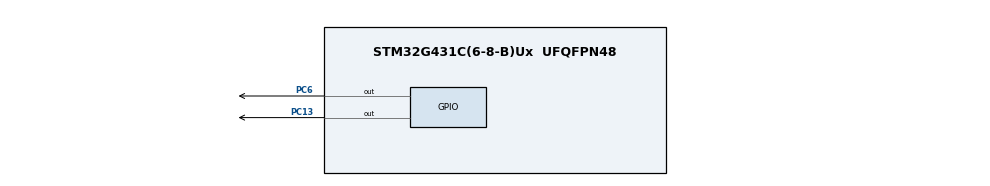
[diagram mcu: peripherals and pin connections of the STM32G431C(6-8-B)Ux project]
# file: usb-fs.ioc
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Mcu.Family=STM32G4
Mcu.Name=STM32G431C(6-8-B)Ux
Mcu.Package=UFQFPN48
NVIC.PriorityGroup=NVIC_PRIORITYGROUP_4
PA13.Mode=Serial_Wire
PA13.Signal=SYS_JTMS-SWDIO
PA14.Mode=Serial_Wire
PA14.Signal=SYS_JTCK-SWCLK
PC13.Signal=GPIO_Output
PC6.Signal=GPIO_Output
PF0-OSC_IN.Mode=HSE-External-Oscillator
PF0-OSC_IN.Signal=RCC_OSC_IN
PF1-OSC_OUT.Mode=HSE-External-Oscillator
PF1-OSC_OUT.Signal=RCC_OSC_OUT
ProjectManager.HeapSize=0x200
ProjectManager.StackSize=0x400
ProjectManager.TargetToolchain=STM32CubeIDE
RCC.ADC12Freq_Value=100000000
RCC.AHBFreq_Value=100000000
RCC.APB1Freq_Value=100000000
RCC.APB1TimFreq_Value=100000000
RCC.APB2Freq_Value=100000000
RCC.APB2TimFreq_Value=100000000
RCC.CK48CLockSelection=RCC_USBCLKSOURCE_HSI48
RCC.CortexFreq_Value=100000000
RCC.EXTERNAL_CLOCK_VALUE=12288000
RCC.HCLKFreq_Value=100000000
RCC.HSI48_VALUE=48000000
RCC.HSI_VALUE=16000000
RCC.LSE_VALUE=32768
RCC.PLLM=RCC_PLLM_DIV2
RCC.PLLN=25
RCC.SYSCLKFreq_VALUE=100000000
RCC.SYSCLKSource=RCC_SYSCLKSOURCE_PLLCLK
RCC.USBFreq_Value=48000000
RCC.VCOOutputFreq_Value=200000000
VP_SYS_VS_DBSignals.Mode=DisableDeadBatterySignals
board=custom

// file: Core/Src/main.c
/* USER CODE BEGIN Header */
/**
  ******************************************************************************
  * @file           : main.c
  * @brief          : Main program body
  ******************************************************************************
  * @attention
  *
  * Copyright (c) 2025 STMicroelectronics.
  * All rights reserved.
  *
  * This software is licensed under terms that can be found in the LICENSE file
  * in the root directory of this software component.
  * If no LICENSE file comes with this software, it is provided AS-IS.
  *
  ******************************************************************************
  */
/* USER CODE END Header */
#include "main.h"

/* USER CODE BEGIN Includes */
//#include "usbd_cdc_if.h"
//#include "Serial/sys_serial.h"
/* USER CODE END Includes */

/* USER CODE BEGIN PTD */
//typedef struct __attribute__((packed))
//{
//  uint8_t sop;
//  uint8_t cmd : 3;
//  uint8_t length : 5;
//  uint8_t data[32];
//  uint16_t crc;
//  uint8_t eop;
//} SYS_SERIAL_PacketTypeDef;

/* USER CODE END PTD */

/* USER CODE BEGIN PV */
//SYS_SERIAL_PacketTypeDef packetBuf = {0xAA,
//                                      0,
//                                      0,
//                                      {0},
//                                      0xF0F0,
//                                      0x55};
/* USER CODE END PV */

void SystemClock_Config(void);
static void MX_GPIO_Init(void);

/* USER CODE BEGIN 0 */
//int _write(int file, char *ptr, int len) {
//    CDC_Transmit_FS((uint8_t*) ptr, len); return len;
//}
/* USER CODE END 0 */

int main(void)
{

  /* MCU Configuration--------------------------------------------------------*/

  /* Reset of all peripherals, Initializes the Flash interface and the Systick. */
  LL_APB2_GRP1_EnableClock(LL_APB2_GRP1_PERIPH_SYSCFG);
  LL_APB1_GRP1_EnableClock(LL_APB1_GRP1_PERIPH_PWR);

  /* System interrupt init*/
  NVIC_SetPriorityGrouping(NVIC_PRIORITYGROUP_4);

  /* SysTick_IRQn interrupt configuration */
  NVIC_SetPriority(SysTick_IRQn, NVIC_EncodePriority(NVIC_GetPriorityGrouping(),15, 0));

  /** Disable the internal Pull-Up in Dead Battery pins of UCPD peripheral
  */
  LL_PWR_DisableUCPDDeadBattery();

  /* Configure the system clock */
  SystemClock_Config();

  /* Initialize all configured peripherals */
  MX_GPIO_Init();
  /* USER CODE BEGIN 2 */
//  uint32_t *pTemp = (uint32_t *)&testVar;
//  packetBuf.data[0] = (uint8_t)(*pTemp >> 24);
//  packetBuf.data[1] = (uint8_t)(*pTemp >> 16);
//  packetBuf.data[2] = (uint8_t)(*pTemp >> 8);
//  packetBuf.data[3] = (uint8_t)(*pTemp >> 0);
//  packetBuf.length = 4;

  /* USER CODE END 2 */

  /* Infinite loop */
  while (1)
  {

    /* USER CODE BEGIN 3 */
//	  CDC_Transmit_FS((uint8_t *)&packetBuf, sizeof(packetBuf));
//    printf("%d\r\n", sizeof(packetBuf));
//    SYS_Serial_SendSamples(&vcp, testVar1, 8);
//    HAL_Delay(2000);
    LL_GPIO_TogglePin(GPIOC, LL_GPIO_PIN_6);
    LL_GPIO_TogglePin(GPIOC, LL_GPIO_PIN_13);
    LL_mDelay(1000);
  }
  /* USER CODE END 3 */
}

void SystemClock_Config(void)
{
  LL_FLASH_SetLatency(LL_FLASH_LATENCY_3);
  while(LL_FLASH_GetLatency() != LL_FLASH_LATENCY_3)
  {
  }
  LL_PWR_SetRegulVoltageScaling(LL_PWR_REGU_VOLTAGE_SCALE1);
  LL_RCC_HSI_Enable();
   /* Wait till HSI is ready */
  while(LL_RCC_HSI_IsReady() != 1)
  {
  }

  LL_RCC_HSI_SetCalibTrimming(64);
  LL_RCC_PLL_ConfigDomain_SYS(LL_RCC_PLLSOURCE_HSI, LL_RCC_PLLM_DIV_2, 25, LL_RCC_PLLR_DIV_2);
  LL_RCC_PLL_EnableDomain_SYS();
  LL_RCC_PLL_Enable();
   /* Wait till PLL is ready */
  while(LL_RCC_PLL_IsReady() != 1)
  {
  }

  LL_RCC_SetSysClkSource(LL_RCC_SYS_CLKSOURCE_PLL);
  LL_RCC_SetAHBPrescaler(LL_RCC_SYSCLK_DIV_2);
   /* Wait till System clock is ready */
  while(LL_RCC_GetSysClkSource() != LL_RCC_SYS_CLKSOURCE_STATUS_PLL)
  {
  }

  /* Insure 1us transition state at intermediate medium speed clock*/
  for (__IO uint32_t i = (170 >> 1); i !=0; i--);

  /* Set AHB prescaler*/
  LL_RCC_SetAHBPrescaler(LL_RCC_SYSCLK_DIV_1);
  LL_RCC_SetAPB1Prescaler(LL_RCC_APB1_DIV_1);
  LL_RCC_SetAPB2Prescaler(LL_RCC_APB2_DIV_1);

  LL_Init1msTick(100000000);

  LL_SetSystemCoreClock(100000000);
}

static void MX_GPIO_Init(void)
{
  LL_GPIO_InitTypeDef GPIO_InitStruct = {0};

  /* GPIO Ports Clock Enable */
  LL_AHB2_GRP1_EnableClock(LL_AHB2_GRP1_PERIPH_GPIOC);
  LL_AHB2_GRP1_EnableClock(LL_AHB2_GRP1_PERIPH_GPIOF);
  LL_AHB2_GRP1_EnableClock(LL_AHB2_GRP1_PERIPH_GPIOG);
  LL_AHB2_GRP1_EnableClock(LL_AHB2_GRP1_PERIPH_GPIOA);
  LL_AHB2_GRP1_EnableClock(LL_AHB2_GRP1_PERIPH_GPIOB);

  /**/
  LL_GPIO_ResetOutputPin(GPIOC, LL_GPIO_PIN_13);

  /**/
  LL_GPIO_ResetOutputPin(GPIOC, LL_GPIO_PIN_6);

  /**/
  GPIO_InitStruct.Pin = LL_GPIO_PIN_13;
  GPIO_InitStruct.Mode = LL_GPIO_MODE_OUTPUT;
  GPIO_InitStruct.Speed = LL_GPIO_SPEED_FREQ_LOW;
  GPIO_InitStruct.OutputType = LL_GPIO_OUTPUT_PUSHPULL;
  GPIO_InitStruct.Pull = LL_GPIO_PULL_NO;
  LL_GPIO_Init(GPIOC, &GPIO_InitStruct);

  /**/
  GPIO_InitStruct.Pin = LL_GPIO_PIN_14;
  GPIO_InitStruct.Mode = LL_GPIO_MODE_ANALOG;
  GPIO_InitStruct.Pull = LL_GPIO_PULL_NO;
  LL_GPIO_Init(GPIOC, &GPIO_InitStruct);

  /**/
  GPIO_InitStruct.Pin = LL_GPIO_PIN_15;
  GPIO_InitStruct.Mode = LL_GPIO_MODE_ANALOG;
  GPIO_InitStruct.Pull = LL_GPIO_PULL_NO;
  LL_GPIO_Init(GPIOC, &GPIO_InitStruct);

  /**/
  GPIO_InitStruct.Pin = LL_GPIO_PIN_10;
  GPIO_InitStruct.Mode = LL_GPIO_MODE_ANALOG;
  GPIO_InitStruct.Pull = LL_GPIO_PULL_NO;
  LL_GPIO_Init(GPIOG, &GPIO_InitStruct);

  /**/
  GPIO_InitStruct.Pin = LL_GPIO_PIN_0;
  GPIO_InitStruct.Mode = LL_GPIO_MODE_ANALOG;
  GPIO_InitStruct.Pull = LL_GPIO_PULL_NO;
  LL_GPIO_Init(GPIOA, &GPIO_InitStruct);

  /**/
  GPIO_InitStruct.Pin = LL_GPIO_PIN_1;
  GPIO_InitStruct.Mode = LL_GPIO_MODE_ANALOG;
  GPIO_InitStruct.Pull = LL_GPIO_PULL_NO;
  LL_GPIO_Init(GPIOA, &GPIO_InitStruct);

  /**/
  GPIO_InitStruct.Pin = LL_GPIO_PIN_2;
  GPIO_InitStruct.Mode = LL_GPIO_MODE_ANALOG;
  GPIO_InitStruct.Pull = LL_GPIO_PULL_NO;
  LL_GPIO_Init(GPIOA, &GPIO_InitStruct);

  /**/
  GPIO_InitStruct.Pin = LL_GPIO_PIN_3;
  GPIO_InitStruct.Mode = LL_GPIO_MODE_ANALOG;
  GPIO_InitStruct.Pull = LL_GPIO_PULL_NO;
  LL_GPIO_Init(GPIOA, &GPIO_InitStruct);

  /**/
  GPIO_InitStruct.Pin = LL_GPIO_PIN_4;
  GPIO_InitStruct.Mode = LL_GPIO_MODE_ANALOG;
  GPIO_InitStruct.Pull = LL_GPIO_PULL_NO;
  LL_GPIO_Init(GPIOA, &GPIO_InitStruct);

  /**/
  GPIO_InitStruct.Pin = LL_GPIO_PIN_5;
  GPIO_InitStruct.Mode = LL_GPIO_MODE_ANALOG;
  GPIO_InitStruct.Pull = LL_GPIO_PULL_NO;
  LL_GPIO_Init(GPIOA, &GPIO_InitStruct);

  /**/
  GPIO_InitStruct.Pin = LL_GPIO_PIN_6;
  GPIO_InitStruct.Mode = LL_GPIO_MODE_ANALOG;
  GPIO_InitStruct.Pull = LL_GPIO_PULL_NO;
  LL_GPIO_Init(GPIOA, &GPIO_InitStruct);

  /**/
  GPIO_InitStruct.Pin = LL_GPIO_PIN_7;
  GPIO_InitStruct.Mode = LL_GPIO_MODE_ANALOG;
  GPIO_InitStruct.Pull = LL_GPIO_PULL_NO;
  LL_GPIO_Init(GPIOA, &GPIO_InitStruct);

  /**/
  GPIO_InitStruct.Pin = LL_GPIO_PIN_4;
  GPIO_InitStruct.Mode = LL_GPIO_MODE_ANALOG;
  GPIO_InitStruct.Pull = LL_GPIO_PULL_NO;
  LL_GPIO_Init(GPIOC, &GPIO_InitStruct);

  /**/
  GPIO_InitStruct.Pin = LL_GPIO_PIN_0;
  GPIO_InitStruct.Mode = LL_GPIO_MODE_ANALOG;
  GPIO_InitStruct.Pull = LL_GPIO_PULL_NO;
  LL_GPIO_Init(GPIOB, &GPIO_InitStruct);

  /**/
  GPIO_InitStruct.Pin = LL_GPIO_PIN_1;
  GPIO_InitStruct.Mode = LL_GPIO_MODE_ANALOG;
  GPIO_InitStruct.Pull = LL_GPIO_PULL_NO;
  LL_GPIO_Init(GPIOB, &GPIO_InitStruct);

  /**/
  GPIO_InitStruct.Pin = LL_GPIO_PIN_2;
  GPIO_InitStruct.Mode = LL_GPIO_MODE_ANALOG;
  GPIO_InitStruct.Pull = LL_GPIO_PULL_NO;
  LL_GPIO_Init(GPIOB, &GPIO_InitStruct);

  /**/
  GPIO_InitStruct.Pin = LL_GPIO_PIN_10;
  GPIO_InitStruct.Mode = LL_GPIO_MODE_ANALOG;
  GPIO_InitStruct.Pull = LL_GPIO_PULL_NO;
  LL_GPIO_Init(GPIOB, &GPIO_InitStruct);

  /**/
  GPIO_InitStruct.Pin = LL_GPIO_PIN_11;
  GPIO_InitStruct.Mode = LL_GPIO_MODE_ANALOG;
  GPIO_InitStruct.Pull = LL_GPIO_PULL_NO;
  LL_GPIO_Init(GPIOB, &GPIO_InitStruct);

  /**/
  GPIO_InitStruct.Pin = LL_GPIO_PIN_12;
  GPIO_InitStruct.Mode = LL_GPIO_MODE_ANALOG;
  GPIO_InitStruct.Pull = LL_GPIO_PULL_NO;
  LL_GPIO_Init(GPIOB, &GPIO_InitStruct);

  /**/
  GPIO_InitStruct.Pin = LL_GPIO_PIN_13;
  GPIO_InitStruct.Mode = LL_GPIO_MODE_ANALOG;
  GPIO_InitStruct.Pull = LL_GPIO_PULL_NO;
  LL_GPIO_Init(GPIOB, &GPIO_InitStruct);

  /**/
  GPIO_InitStruct.Pin = LL_GPIO_PIN_14;
  GPIO_InitStruct.Mode = LL_GPIO_MODE_ANALOG;
  GPIO_InitStruct.Pull = LL_GPIO_PULL_NO;
  LL_GPIO_Init(GPIOB, &GPIO_InitStruct);

  /**/
  GPIO_InitStruct.Pin = LL_GPIO_PIN_15;
  GPIO_InitStruct.Mode = LL_GPIO_MODE_ANALOG;
  GPIO_InitStruct.Pull = LL_GPIO_PULL_NO;
  LL_GPIO_Init(GPIOB, &GPIO_InitStruct);

  /**/
  GPIO_InitStruct.Pin = LL_GPIO_PIN_6;
  GPIO_InitStruct.Mode = LL_GPIO_MODE_OUTPUT;
  GPIO_InitStruct.Speed = LL_GPIO_SPEED_FREQ_LOW;
  GPIO_InitStruct.OutputType = LL_GPIO_OUTPUT_PUSHPULL;
  GPIO_InitStruct.Pull = LL_GPIO_PULL_NO;
  LL_GPIO_Init(GPIOC, &GPIO_InitStruct);

  /**/
  GPIO_InitStruct.Pin = LL_GPIO_PIN_8;
  GPIO_InitStruct.Mode = LL_GPIO_MODE_ANALOG;
  GPIO_InitStruct.Pull = LL_GPIO_PULL_NO;
  LL_GPIO_Init(GPIOA, &GPIO_InitStruct);

  /**/
  GPIO_InitStruct.Pin = LL_GPIO_PIN_9;
  GPIO_InitStruct.Mode = LL_GPIO_MODE_ANALOG;
  GPIO_InitStruct.Pull = LL_GPIO_PULL_NO;
  LL_GPIO_Init(GPIOA, &GPIO_InitStruct);

  /**/
  GPIO_InitStruct.Pin = LL_GPIO_PIN_10;
  GPIO_InitStruct.Mode = LL_GPIO_MODE_ANALOG;
  GPIO_InitStruct.Pull = LL_GPIO_PULL_NO;
  LL_GPIO_Init(GPIOA, &GPIO_InitStruct);

  /**/
  GPIO_InitStruct.Pin = LL_GPIO_PIN_11;
  GPIO_InitStruct.Mode = LL_GPIO_MODE_ANALOG;
  GPIO_InitStruct.Pull = LL_GPIO_PULL_NO;
  LL_GPIO_Init(GPIOA, &GPIO_InitStruct);

  /**/
  GPIO_InitStruct.Pin = LL_GPIO_PIN_12;
  GPIO_InitStruct.Mode = LL_GPIO_MODE_ANALOG;
  GPIO_InitStruct.Pull = LL_GPIO_PULL_NO;
  LL_GPIO_Init(GPIOA, &GPIO_InitStruct);

  /**/
  GPIO_InitStruct.Pin = LL_GPIO_PIN_15;
  GPIO_InitStruct.Mode = LL_GPIO_MODE_ANALOG;
  GPIO_InitStruct.Pull = LL_GPIO_PULL_NO;
  LL_GPIO_Init(GPIOA, &GPIO_InitStruct);

  /**/
  GPIO_InitStruct.Pin = LL_GPIO_PIN_10;
  GPIO_InitStruct.Mode = LL_GPIO_MODE_ANALOG;
  GPIO_InitStruct.Pull = LL_GPIO_PULL_NO;
  LL_GPIO_Init(GPIOC, &GPIO_InitStruct);

  /**/
  GPIO_InitStruct.Pin = LL_GPIO_PIN_11;
  GPIO_InitStruct.Mode = LL_GPIO_MODE_ANALOG;
  GPIO_InitStruct.Pull = LL_GPIO_PULL_NO;
  LL_GPIO_Init(GPIOC, &GPIO_InitStruct);

  /**/
  GPIO_InitStruct.Pin = LL_GPIO_PIN_3;
  GPIO_InitStruct.Mode = LL_GPIO_MODE_ANALOG;
  GPIO_InitStruct.Pull = LL_GPIO_PULL_NO;
  LL_GPIO_Init(GPIOB, &GPIO_InitStruct);

  /**/
  GPIO_InitStruct.Pin = LL_GPIO_PIN_4;
  GPIO_InitStruct.Mode = LL_GPIO_MODE_ANALOG;
  GPIO_InitStruct.Pull = LL_GPIO_PULL_NO;
  LL_GPIO_Init(GPIOB, &GPIO_InitStruct);

  /**/
  GPIO_InitStruct.Pin = LL_GPIO_PIN_5;
  GPIO_InitStruct.Mode = LL_GPIO_MODE_ANALOG;
  GPIO_InitStruct.Pull = LL_GPIO_PULL_NO;
  LL_GPIO_Init(GPIOB, &GPIO_InitStruct);

  /**/
  GPIO_InitStruct.Pin = LL_GPIO_PIN_6;
  GPIO_InitStruct.Mode = LL_GPIO_MODE_ANALOG;
  GPIO_InitStruct.Pull = LL_GPIO_PULL_NO;
  LL_GPIO_Init(GPIOB, &GPIO_InitStruct);

  /**/
  GPIO_InitStruct.Pin = LL_GPIO_PIN_7;
  GPIO_InitStruct.Mode = LL_GPIO_MODE_ANALOG;
  GPIO_InitStruct.Pull = LL_GPIO_PULL_NO;
  LL_GPIO_Init(GPIOB, &GPIO_InitStruct);

  /**/
  GPIO_InitStruct.Pin = LL_GPIO_PIN_8;
  GPIO_InitStruct.Mode = LL_GPIO_MODE_ANALOG;
  GPIO_InitStruct.Pull = LL_GPIO_PULL_NO;
  LL_GPIO_Init(GPIOB, &GPIO_InitStruct);

  /**/
  GPIO_InitStruct.Pin = LL_GPIO_PIN_9;
  GPIO_InitStruct.Mode = LL_GPIO_MODE_ANALOG;
  GPIO_InitStruct.Pull = LL_GPIO_PULL_NO;
  LL_GPIO_Init(GPIOB, &GPIO_InitStruct);

}

void Error_Handler(void)
{
  __disable_irq();
  while (1)
  {
  }
}
